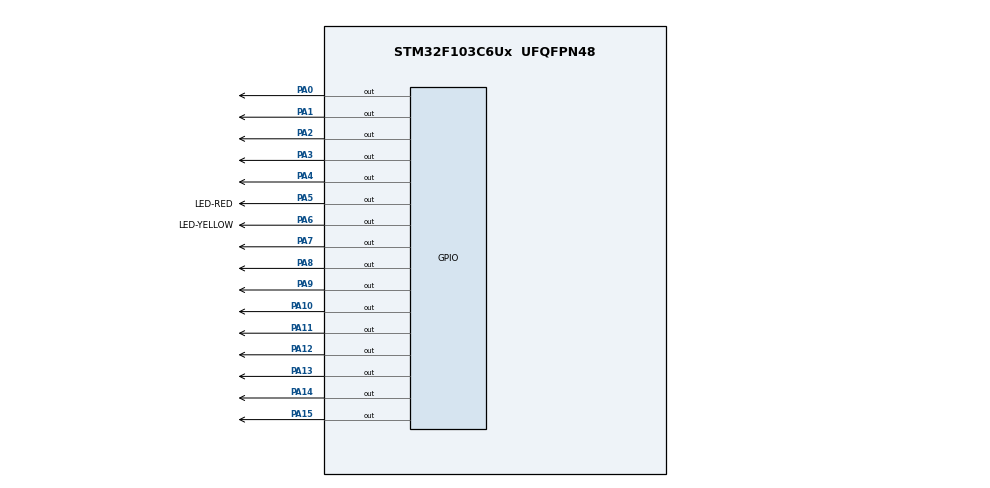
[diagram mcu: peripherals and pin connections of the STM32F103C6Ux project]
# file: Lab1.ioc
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Mcu.Family=STM32F1
Mcu.Name=STM32F103C6Ux
Mcu.Package=UFQFPN48
NVIC.PriorityGroup=NVIC_PRIORITYGROUP_4
PA0-WKUP.Signal=GPIO_Output
PA1.Signal=GPIO_Output
PA10.Signal=GPIO_Output
PA11.Signal=GPIO_Output
PA12.Signal=GPIO_Output
PA13.Signal=GPIO_Output
PA14.Signal=GPIO_Output
PA15.Signal=GPIO_Output
PA2.Signal=GPIO_Output
PA3.Signal=GPIO_Output
PA4.Signal=GPIO_Output
PA5.GPIO_Label=LED-RED
PA5.Signal=GPIO_Output
PA6.GPIO_Label=LED-YELLOW
PA6.Signal=GPIO_Output
PA7.Signal=GPIO_Output
PA8.Signal=GPIO_Output
PA9.Signal=GPIO_Output
ProjectManager.HeapSize=0x200
ProjectManager.StackSize=0x400
ProjectManager.TargetToolchain=CMake
RCC.APB1Freq_Value=8000000
RCC.APB2Freq_Value=8000000
VP_SYS_VS_ND.Mode=No_Debug
board=custom

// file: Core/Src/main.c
/* USER CODE BEGIN Header */
/**
 ******************************************************************************
 * @file           : main.c
 * @brief          : Main program body
 ******************************************************************************
 * @attention
 *
 * Copyright (c) 2026 STMicroelectronics.
 * All rights reserved.
 *
 * This software is licensed under terms that can be found in the LICENSE file
 * in the root directory of this software component.
 * If no LICENSE file comes with this software, it is provided AS-IS.
 *
 ******************************************************************************
 */
/* USER CODE END Header */
#include "main.h"
#include "stm32f103x6.h"
#include "stm32f1xx.h"
#include "stm32f1xx_hal.h"
#include "stm32f1xx_hal_gpio.h"

void SystemClock_Config(void);
static void MX_GPIO_Init(void);

/* USER CODE BEGIN 0 */
typedef enum { TRAFFIC_RED, TRAFFIC_GREEN, TRAFFIC_YELLOW } TrafficState;
void setTrafficLight(TrafficState state) {
  HAL_GPIO_WritePin(GPIOA, GPIO_PIN_5 | GPIO_PIN_6 | GPIO_PIN_7, GPIO_PIN_SET);
  switch (state) {
  case TRAFFIC_RED:
    HAL_GPIO_WritePin(GPIOA, GPIO_PIN_5, GPIO_PIN_RESET);
    break;
  case TRAFFIC_GREEN:
    HAL_GPIO_WritePin(GPIOA, GPIO_PIN_7, GPIO_PIN_RESET);
    break;
  case TRAFFIC_YELLOW:
    HAL_GPIO_WritePin(GPIOA, GPIO_PIN_6, GPIO_PIN_RESET);
    break;
  default:
    break;
  }
}
/* USER CODE END 0 */

int main(void) {

  /* MCU Configuration--------------------------------------------------------*/

  /* Reset of all peripherals, Initializes the Flash interface and the Systick.
   */
  HAL_Init();

  /* Configure the system clock */
  SystemClock_Config();

  /* Initialize all configured peripherals */
  MX_GPIO_Init();

  /* Infinite loop */
  while (1) {

    setTrafficLight(TRAFFIC_RED);
    HAL_Delay(5000);

    setTrafficLight(TRAFFIC_GREEN);
    HAL_Delay(3000);

    setTrafficLight(TRAFFIC_YELLOW);
    HAL_Delay(2000);

  }
}

void SystemClock_Config(void) {
  RCC_OscInitTypeDef RCC_OscInitStruct = {0};
  RCC_ClkInitTypeDef RCC_ClkInitStruct = {0};

  /** Initializes the RCC Oscillators according to the specified parameters
   * in the RCC_OscInitTypeDef structure.
   */
  RCC_OscInitStruct.OscillatorType = RCC_OSCILLATORTYPE_HSI;
  RCC_OscInitStruct.HSIState = RCC_HSI_ON;
  RCC_OscInitStruct.HSICalibrationValue = RCC_HSICALIBRATION_DEFAULT;
  RCC_OscInitStruct.PLL.PLLState = RCC_PLL_NONE;
  if (HAL_RCC_OscConfig(&RCC_OscInitStruct) != HAL_OK) {
    Error_Handler();
  }

  /** Initializes the CPU, AHB and APB buses clocks
   */
  RCC_ClkInitStruct.ClockType = RCC_CLOCKTYPE_HCLK | RCC_CLOCKTYPE_SYSCLK |
                                RCC_CLOCKTYPE_PCLK1 | RCC_CLOCKTYPE_PCLK2;
  RCC_ClkInitStruct.SYSCLKSource = RCC_SYSCLKSOURCE_HSI;
  RCC_ClkInitStruct.AHBCLKDivider = RCC_SYSCLK_DIV1;
  RCC_ClkInitStruct.APB1CLKDivider = RCC_HCLK_DIV1;
  RCC_ClkInitStruct.APB2CLKDivider = RCC_HCLK_DIV1;

  if (HAL_RCC_ClockConfig(&RCC_ClkInitStruct, FLASH_LATENCY_0) != HAL_OK) {
    Error_Handler();
  }
}

static void MX_GPIO_Init(void) {
  GPIO_InitTypeDef GPIO_InitStruct = {0};

  /* GPIO Ports Clock Enable */
  __HAL_RCC_GPIOA_CLK_ENABLE();

  /*Configure GPIO pin Output Level */
  HAL_GPIO_WritePin(GPIOA, LED_RED_Pin | LED_YELLOW_Pin | LED_GREEN_Pin,
                    GPIO_PIN_RESET);

  /*Configure GPIO pins : LED_RED_Pin LED_YELLOW_Pin LED_GREEN_Pin */
  GPIO_InitStruct.Pin = LED_RED_Pin | LED_YELLOW_Pin | LED_GREEN_Pin;
  GPIO_InitStruct.Mode = GPIO_MODE_OUTPUT_PP;
  GPIO_InitStruct.Pull = GPIO_NOPULL;
  GPIO_InitStruct.Speed = GPIO_SPEED_FREQ_LOW;
  HAL_GPIO_Init(GPIOA, &GPIO_InitStruct);

}

void Error_Handler(void) {
  __disable_irq();
  while (1) {
  }
}
#ifdef USE_FULL_ASSERT
/**
 * @brief  Reports the name of the source file and the source line number
 *         where the assert_param error has occurred.
 * @param  file: pointer to the source file name
 * @param  line: assert_param error line source number
 * @retval None
 */
void assert_failed(uint8_t *file, uint32_t line) {
  /* USER CODE BEGIN 6 */
  /* User can add his own implementation to report the file name and line
     number, ex: printf("Wrong parameters value: file %s on line %d\r\n", file,
     line) */
  /* USER CODE END 6 */
}
#endif /* USE_FULL_ASSERT */
